# STM32F100 register map
Vendor: STMicroelectronics; File version: 1.0
Compact course SVD for the STM32F100 (C for Hardware mini-course). Covers RCC, GPIOA, USART1, and SysTick only.
CPU: CM3 r1p1, little endian, no MPU, no FPU, 4 interrupt priority bits
Registers are 32-bit, read-write, reset 0x0 unless marked. A register's access mark holds for its fields unless they carry their own. Offsets are from the block's base; lines under a group give offsets from that group; [hi:lo] are bit positions; {n}, {i} and the like mark numbered series; 'fields as' and 'values as' point back to an identical list; <NAME> marks a mode.

## Memory map
0x40010800 GPIOA size 0x1C — General-purpose I/O port A
0x40013800 USART1 size 0x1C — Universal synchronous asynchronous receiver transmitter 1
0x40021000 RCC size 0x28 — Reset and clock control
0xE000E010 STK size 0x10 — System timer (SysTick)

## RCC — Reset and clock control
Base 0x40021000
0x00 CR reset 0x83 — Clock control register
0x04 CFGR — Clock configuration register
0x08 CIR — Clock interrupt register
0x0C APB2RSTR — APB2 peripheral reset register
0x10 APB1RSTR — APB1 peripheral reset register
0x14 AHBENR — AHB peripheral clock enable register
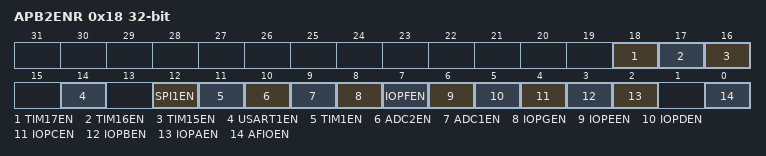
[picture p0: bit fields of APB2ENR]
0x18 APB2ENR — APB2 peripheral clock enable register
  [18] TIM17EN, [17] TIM16EN, [16] TIM15EN, [14] USART1EN, [12] SPI1EN, [11] TIM1EN, [10] ADC2EN, [9] ADC1EN, [8] IOPGEN, [7] IOPFEN, [6] IOPEEN, [5] IOPDEN, [4] IOPCEN, [3] IOPBEN, [2] IOPAEN, [0] AFIOEN
0x1C APB1ENR — APB1 peripheral clock enable register

## GPIOA — General-purpose I/O port A
Base 0x40010800
0x00 CRL reset 0x44444444 — Port configuration register low
0x04 CRH reset 0x44444444 — Port configuration register high
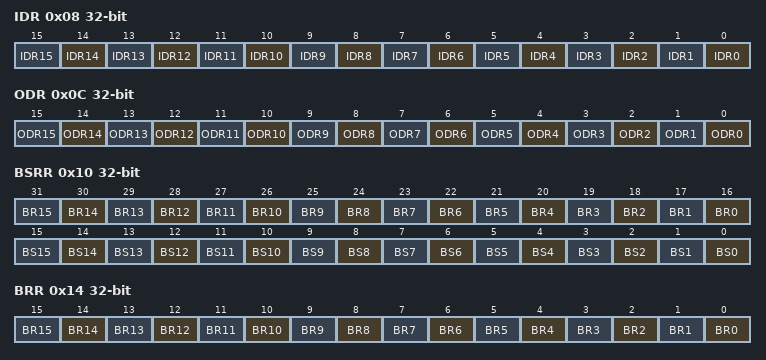
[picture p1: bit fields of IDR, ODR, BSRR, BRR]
0x08 IDR ro — Input data register
  [n] IDR{n} (n=0..15)
0x0C ODR — Output data register
  [n] ODR{n} (n=0..15)
0x10 BSRR wo — Bit set/reset register
  [n+16] BR{n} (n=0..15), [n] BS{n} (n=0..15)
0x14 BRR wo — Bit reset register
  [n] BR{n} (n=0..15)
0x18 LCKR — Configuration lock register

## USART1 — Universal synchronous asynchronous receiver transmitter 1
Base 0x40013800
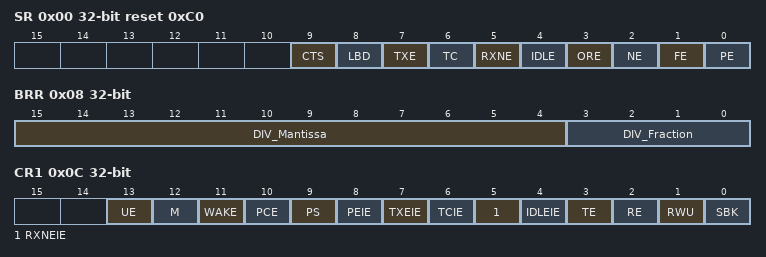
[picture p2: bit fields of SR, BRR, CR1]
0x00 SR reset 0xC0 — Status register
  [9] CTS, [8] LBD, [7] TXE, [6] TC, [5] RXNE, [4] IDLE, [3] ORE, [2] NE, [1] FE, [0] PE
0x04 DR — Data register
0x08 BRR — Baud rate register
  [15:4] DIV_Mantissa, [3:0] DIV_Fraction
0x0C CR1 — Control register 1
  [13] UE, [12] M, [11] WAKE, [10] PCE, [9] PS, [8] PEIE, [7] TXEIE, [6] TCIE, [5] RXNEIE, [4] IDLEIE, [3] TE, [2] RE, [1] RWU, [0] SBK
0x10 CR2 — Control register 2
0x14 CR3 — Control register 3
0x18 GTPR — Guard time and prescaler register

## STK — System timer (SysTick)
Base 0xE000E010
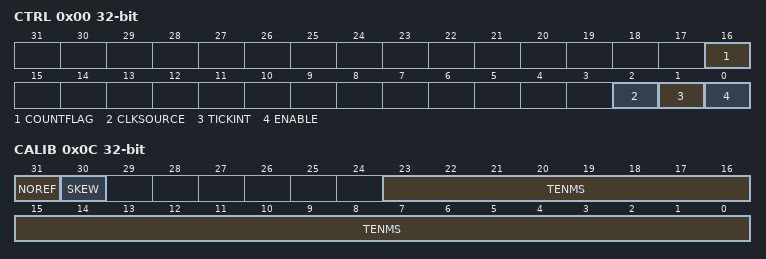
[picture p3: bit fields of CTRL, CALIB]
0x00 CTRL — SysTick control and status register
  [16] COUNTFLAG, [2] CLKSOURCE, [1] TICKINT, [0] ENABLE
0x04 LOAD — SysTick reload value register
  [23:0] RELOAD
0x08 VAL — SysTick current value register
  [23:0] CURRENT
0x0C CALIB ro — SysTick calibration register
  [31] NOREF, [30] SKEW, [23:0] TENMS
